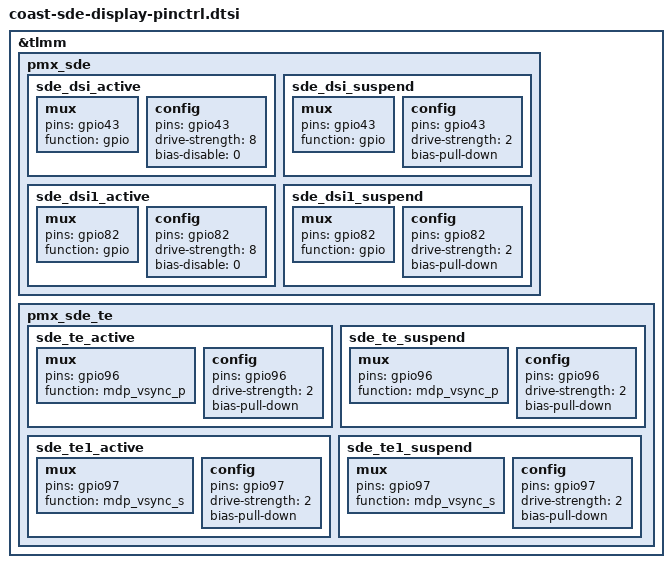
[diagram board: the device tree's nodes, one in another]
// SPDX-License-Identifier: BSD-3-Clause
/*
 * Copyright (c) Qualcomm Technologies, Inc. and/or its subsidiaries.
 */

&tlmm {
	pmx_sde: pmx_sde {
		sde_dsi_active: sde_dsi_active {
			mux {
				pins = "gpio43";
				function = "gpio";
			};

			config {
				pins = "gpio43";
				drive-strength = <8>;   /* 8 mA */
				bias-disable = <0>;   /* no pull */
			};
		};

		sde_dsi_suspend: sde_dsi_suspend {
			mux {
				pins = "gpio43";
				function = "gpio";
			};

			config {
				pins = "gpio43";
				drive-strength = <2>;   /* 2 mA */
				bias-pull-down;         /* PULL DOWN */
			};
		};

		sde_dsi1_active: sde_dsi1_active {
			mux {
				pins = "gpio82";
				function = "gpio";
			};

			config {
				pins = "gpio82";
				drive-strength = <8>;   /* 8 mA */
				bias-disable = <0>;   /* no pull */
			};
		};

		sde_dsi1_suspend: sde_dsi1_suspend {
			mux {
				pins = "gpio82";
				function = "gpio";
			};

			config {
				pins = "gpio82";
				drive-strength = <2>;   /* 2 mA */
				bias-pull-down;         /* PULL DOWN */
			};
		};
	};

	pmx_sde_te: pmx_sde_te {
		sde_te_active: sde_te_active {
			mux {
				pins = "gpio96";
				function = "mdp_vsync_p";
			};

			config {
				pins = "gpio96";
				drive-strength = <2>;   /* 2 mA */
				bias-pull-down;         /* PULL DOWN */
			};
		};

		sde_te_suspend: sde_te_suspend {
			mux {
				pins = "gpio96";
				function = "mdp_vsync_p";
			};

			config {
				pins = "gpio96";
				drive-strength = <2>;   /* 2 mA */
				bias-pull-down;         /* PULL DOWN */
			};
		};

		sde_te1_active: sde_te1_active {
			mux {
				pins = "gpio97";
				function = "mdp_vsync_s";
			};

			config {
				pins = "gpio97";
				drive-strength = <2>;   /* 2 mA */
				bias-pull-down;         /* PULL DOWN */
			};
		};

		sde_te1_suspend: sde_te1_suspend {
			mux {
				pins = "gpio97";
				function = "mdp_vsync_s";
			};

			config {
				pins = "gpio97";
				drive-strength = <2>;   /* 2 mA */
				bias-pull-down;         /* PULL DOWN */
			};
		};
	};
};
